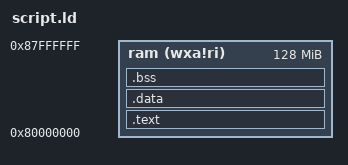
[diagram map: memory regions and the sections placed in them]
OUTPUT_ARCH( "riscv" )

ENTRY( _start )

MEMORY
{
  ram   (wxa!ri) : ORIGIN = 0x80000000, LENGTH = 128M  /*Found in qemu src file*/
}

PHDRS
{
  text PT_LOAD;
  data PT_LOAD;
  bss PT_LOAD;
}

SECTIONS
{
  .text : {
    PROVIDE(_text_start = .);
    *(.text.init) *(.text .text.*)
    PROVIDE(_text_end = .);
  } >ram AT>ram :text
   PROVIDE(_global_pointer = .);

  .data : {
    . = ALIGN(4096);
    PROVIDE(_data_start = .);
    *(.sdata .sdata.*) *(.data .data.*)
    PROVIDE(_data_end = .);
  } >ram AT>ram :data

  .bss :{
    PROVIDE(_bss_start = .);
    *(.sbss .sbss.*) *(.bss .bss.*)
    PROVIDE(_bss_end = .);
  } >ram AT>ram :bss

  PROVIDE(_memory_start = ORIGIN(ram));
  PROVIDE(_stack = _bss_end);                 /*stack grows downwards*/
  PROVIDE(_heap_start = _stack + 0x80000000); /*heap grows upwards*/
}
